AUTOSAR XML (schema 4-2-2)
package /ComponentTypes
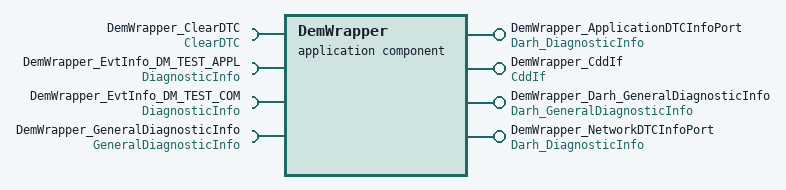
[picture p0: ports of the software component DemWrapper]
  application sw component type DemWrapper
    4 x provide port:
      DemWrapper_ApplicationDTCInfoPort: server-com-spec{operation=GetDTCOfEvent, queue-length=1}, provided-interface=Darh_DiagnosticInfo
      DemWrapper_CddIf: server-com-spec{operation=ClearDTC, queue-length=1}, provided-interface=CddIf
      DemWrapper_Darh_GeneralDiagnosticInfo: provided-com-specs=[{operation=GetDTCOfEvent, queue-length=1}, {operation=GetEventFreezeFrameData, queue-length=1}], provided-interface=Darh_GeneralDiagnosticInfo
      DemWrapper_NetworkDTCInfoPort: server-com-spec{operation=GetDTCOfEvent, queue-length=1}, provided-interface=Darh_DiagnosticInfo
    4 x require port:
      DemWrapper_ClearDTC: required-com-specs=[ClearDTC, SelectDTC], required-interface=ClearDTC
      DemWrapper_EvtInfo_DM_TEST_APPL: required-interface=DiagnosticInfo
        required-com-specs:
          GetDebouncingOfEvent
          GetDTCOfEvent
          GetEventEnableCondition
          GetEventExtendedDataRecordEx
          GetEventFailed
          GetEventFreezeFrameDataEx
          GetEventStatus
          GetEventTested
          GetEventUdsStatus
          GetFaultDetectionCounter
          GetMonitorStatus
      DemWrapper_EvtInfo_DM_TEST_COM: required-interface=DiagnosticInfo
        required-com-specs:
          GetDebouncingOfEvent
          GetDTCOfEvent
          GetEventEnableCondition
          GetEventExtendedDataRecordEx
          GetEventFailed
          GetEventFreezeFrameDataEx
          GetEventStatus
          GetEventTested
          GetEventUdsStatus
          GetFaultDetectionCounter
          GetMonitorStatus
      DemWrapper_GeneralDiagnosticInfo: required-interface=GeneralDiagnosticInfo
        required-com-specs:
          GetDebouncingOfEvent
          GetDTCOfEvent
          GetEventEnableCondition
          GetEventExtendedDataRecordEx
          GetEventFailed
          GetEventFreezeFrameDataEx
          GetEventStatus
          GetEventTested
          GetEventUdsStatus
          GetFaultDetectionCounter
          GetMonitorStatus
    behavior DemWrapper_InternalBehavior
      4 x operation invoked event:
        OIT_DemWrapper_ApplicationDTCInfoPort_GetDTCOfEvent_DemWrapper_ApplicationDTCInfoPort_GetDTCOfEvent: start-on-event=DemWrapper_ApplicationDTCInfoPort_GetDTCOfEvent, operation=DemWrapper_ApplicationDTCInfoPort.GetDTCOfEvent
        OIT_DemWrapper_CddIf_ClearDTC_DemWrapper_CddIf_ClearDTC: start-on-event=DemWrapper_CddIf_ClearDTC, operation=DemWrapper_CddIf.ClearDTC
        OIT_DemWrapper_Darh_GeneralDiagnosticInfo_GetDTCOfEvent_DemWrapper_Darh_GeneralDiagnosticInfo_GetDTCOfEvent: start-on-event=DemWrapper_Darh_GeneralDiagnosticInfo_GetDTCOfEvent, operation=DemWrapper_Darh_GeneralDiagnosticInfo.GetDTCOfEvent
        OIT_DemWrapper_Darh_GeneralDiagnosticInfo_GetEventFreezeFrameData_DemWrapper_Darh_GeneralDiagnosticInfo_GetEventFreezeFrameData: start-on-event=DemWrapper_Darh_GeneralDiagnosticInfo_GetEventFreezeFrameData, operation=DemWrapper_Darh_GeneralDiagnosticInfo.GetEventFreezeFrameData
      init event DemWrapper_InitEvent: start-on-event=DemWrapper_Init
      operation invoked event OIT_DemWrapper_NetworkDTCInfoPort_GetDTCOfEvent_DemWrapper_NetworkDTCInfoPort_GetDTCOfEvent: start-on-event=DemWrapper_NetworkDTCInfoPort_GetDTCOfEvent, operation=DemWrapper_NetworkDTCInfoPort.GetDTCOfEvent
      6 x runnable:
        DemWrapper_ApplicationDTCInfoPort_GetDTCOfEvent
          sync call SC_DemWrapper_EvtInfo_DM_TEST_APPL_GetDTCOfEvent: operation=DemWrapper_EvtInfo_DM_TEST_APPL.GetDTCOfEvent, timeout=0
        DemWrapper_CddIf_ClearDTC
          sync call SC_DemWrapper_ClearDTC_SelectDTC: operation=DemWrapper_ClearDTC.SelectDTC, timeout=0
        DemWrapper_Darh_GeneralDiagnosticInfo_GetDTCOfEvent
          sync call SC_DemWrapper_GeneralDiagnosticInfo_GetDTCOfEvent: operation=DemWrapper_GeneralDiagnosticInfo.GetDTCOfEvent, timeout=0
        DemWrapper_Darh_GeneralDiagnosticInfo_GetEventFreezeFrameData
          sync call SC_DemWrapper_GeneralDiagnosticInfo_GetEventFreezeFrameDataEx: operation=DemWrapper_GeneralDiagnosticInfo.GetEventFreezeFrameDataEx, timeout=0
        DemWrapper_Init
        DemWrapper_NetworkDTCInfoPort_GetDTCOfEvent
          sync call SC_DemWrapper_EvtInfo_DM_TEST_COM_GetDTCOfEvent: operation=DemWrapper_EvtInfo_DM_TEST_COM.GetDTCOfEvent, timeout=0
  swc implementation DemWrapper_Implementation: behavior=DemWrapper_InternalBehavior
    code-descriptors:
      code Default: artifact-descriptors=autosar-engineering-object={short-label=Default, category=SWSRC}
